# MINI51XAE_v1 register map
File version: 1.0
Registers are 32-bit, read-write, reset 0x0 unless marked. A register's access mark holds for its fields unless they carry their own. Offsets are from the block's base; [hi:lo] are bit positions.

## SYS — SYS Register Map
Base 0x50000000
0x00 SYS_PDID ro reset not defined — Part Device Identification Number Register
  [31:0] PDID — Product Device Identification Number. This register reflects the device part number code. Software can read this register to identify which device is used.
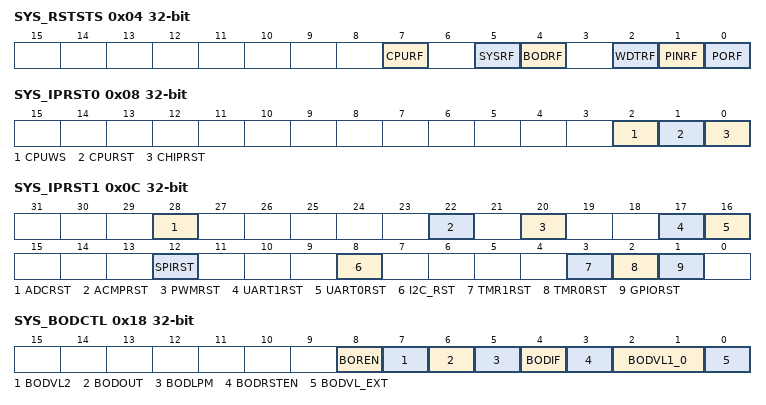
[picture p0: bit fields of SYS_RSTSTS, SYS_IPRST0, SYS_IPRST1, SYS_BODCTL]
0x04 SYS_RSTSTS (reset mask 0xFFFFFF00) — System Reset Source Register
  [7] CPURF — CPU Reset Flag. The CPURF flag is set by hardware if software writes CPURST (SYS_IPRST0[1]) 1 to reset Cortex-M0 core and Flash memory controller (FMC). Note: Software can write 1 to clear this bit to zero.
    0=No reset from CPU; 1=Cortex-M0 core and FMC are reset by software setting CPURST to 1
  [5] SYSRF — MCU Reset Flag. The SYSRF flag is set by the "reset signal" from the Cortex-M0 core to indicate the previous reset source. Note: Software can write 1 to clear this bit to zero.
    0=No reset from Cortex-M0; 1=The Cortex-M0 had issued the reset signal to reset the system by writing 1 to bit SYSRESETREQ (AIRCR[2]), Application Interrupt and Reset Control Register, address = 0xE000ED0C) in system control registers of Cortex-M0 core
  [4] BODRF — Brown-Out Detector Reset Flag. The BODRF flag is set by the "reset signal" from the Brown-out Detector to indicate the previous reset source. Note: Software can write 1 to clear this bit to zero.
    0=No reset from BOD; 1=The BOD had issued the reset signal to reset the system
  [2] WDTRF — Watchdog Reset Flag. The RSTS_WDT flag is set by the "reset signal" from the Watchdog timer to indicate the previous reset source. Note: Software can write 1 to clear this bit to zero.
    0=No reset from Watchdog timer; 1=The Watchdog timer had issued the reset signal to reset the system
  [1] PINRF — Reset Pin Reset Flag. The PINRF flag is set by the "reset signal" from the /RESET pin to indicate the previous reset source. Note: Software can write 1 to clear this bit to zero.
    0=No reset from pin /RESET pin; 1=The /RESET pin had issued the reset signal to reset the system
  [0] PORF — Power-On Reset Flag. The PORF flag is set by the "reset signal", which is from the Power-On Reset (POR) controller or bit CHIPRST (SYS_IPRST0[0]), to indicate the previous reset source. Note: Software can write 1 to clear this bit to zero.
    0=No reset from POR or CHIPRST; 1=The Power-on-Reset (POR) or CHIPRST had issued the reset signal to reset the system
0x08 SYS_IPRST0 — Peripheral Reset Control Resister 1
  [2] CPUWS — CPU Wait-State Control For Flash Memory Access. 0: Insert one wait-state when access Flash. 1: Non-insert wait-state when access Flash. Note: When HCLK frequency is faster than 44MHz, insert one wait state is necessary.
  [1] CPURST — CPU Kernel One Shot Reset. Setting this bit will reset the CPU kernel, and this bit will automatically return to 0 after the 2 clock cycles. Note: This bit is the protected bit, and programming it needs to write 0x59, 0x16, and 0x88 to address 0x5000_0100 to disable register protection. Refer to the register REGLCTL at address SYS_BA + 0x100.
    0=Normal; 1=Reset CPU
  [0] CHIPRST — CHIP One-Shot Reset (Write Protect). Setting this bit will reset the CHIP, including CPU kernel and all peripherals, and this bit will automatically return to 0 after the 2 clock cycles. The CHIPRST is the same as the POR reset, and all the chip module is reset and the chip settings from flash are also reload. Note: This bit is the protected bit, and programming it needs to write 0x59, 0x16, and 0x88 to address 0x5000_0100 to disable register protection. Refer to the register REGLCTL at address SYS_BA + 0x100.
    0=Chip normal operation; 1=CHIP one-shot reset
0x0C SYS_IPRST1 — Peripheral Reset Control Resister 2
  [28] ADCRST — ADC Controller Reset
    0=ADC block normal operation; 1=ADC block reset
  [22] ACMPRST — ACMP Controller Reset
    0=ACMP block normal operation; 1=ACMP block reset
  [20] PWMRST — PWM Controller Reset
    0=PWM block normal operation; 1=PWM block reset
  [17] UART1RST — UART1 Controller Reset
    0=UART1 normal operation; 1=UART1 block reset
  [16] UART0RST — UART0 Controller Reset
    0=UART0 normal operation; 1=UART0 block reset
  [12] SPIRST — SPI Controller Reset
    0=SPI block normal operation; 1=SPI block reset
  [8] I2C_RST — I2C Controller Reset
    0=I2C normal operation; 1=I2C block reset
  [3] TMR1RST — Timer1 Controller Reset
    0=Timer1 normal operation; 1=Timer1 block reset
  [2] TMR0RST — Timer0 Controller Reset
    0=Timer0 normal operation; 1=Timer0 block reset
  [1] GPIORST — GPIO (P0~P5) Controller Reset
    0=GPIO normal operation; 1=GPIO reset
0x18 SYS_BODCTL (reset mask 0xFFFFFF00) — Brown-out Detector Control Register
  [8] BOREN — Brown-Out Reset Enable. The bit will enable BOR reset function. When VDD5V lower than 1.7v BOR will reset whole chip. 0: Disable. 1: Enable
  [7] BODVL2 — Brown-Out Detector Threshold Voltage Selection (Initiated Write-Protected Bit). The default value is set by flash controller user configuration register config0 bit[19].
  [6] BODOUT — Brown-Out Detector Output State
    0=Brown-out Detector status output is 0, the detected voltage is higher than BODVL setting; 1=Brown-out Detector status output is 1, the detected voltage is lower than BODVL setting
  [5] BODLPM — Brown-Out Detector Low Power Mode (Write-Protected). The BOD consumes about 100uA in normal mode, the low power mode can reduce the current to about 1/10 but slow the BOD response.
    0=BOD operate in normal mode (default); 1=Enable the BOD low power mode
  [4] BODIF — Brown-Out Detector Interrupt Flag
    0=Brown-out Detector does not detect any voltage draft at VDD down through or up through the voltage of BODVL setting; 1=When Brown-out Detector detects the VDD is dropped through the voltage of BODVL setting or the VDD is raised up through the voltage of BODVL setting, this bit is set to 1 and the Brown-out interrupt is requested if Brown-out interrupt is enabled
  [3] BODRSTEN — Brown-Out Reset Enable (Initiated And Write-Protected Bit). The default value is set by flash controller user configuration register config0 bit[20]. When the BOREN is enabled and the interrupt is asserted, the interrupt will be kept till the BOREN is set to 0. The interrupt for CPU can be blocked by disabling the NVIC in CPU for BOD interrupt or disable the interrupt source by disabling the BOREN and then re-enabling the BOREN function if the BOD function is required.
    0=Brown-out "INTERRUPT" function Enabled; when the Brown-out Detector function is enable and the detected voltage is lower than the threshold, then assert a signal to interrupt the Cortex-M0 CPU; 1=Brown-out "RESET" function Enabled; when the Brown-out Detector function is enable and the detected voltage is lower than the threshold then assert a signal to reset the chip
  [2:1] BODVL1_0 — Brown-Out Detector Threshold Voltage Selection (Initiated Write-Protected Bit)
  [0] BODVL_EXT — Brown-Out Detector Selection Extension (Initiated Write-Protected Bit)
    0=Brown-out detector threshold voltage is selected by the table defined in BODVL[1:0]; 1=Brown-out detector threshold voltage is selected by BODVL[2:0] defined as below
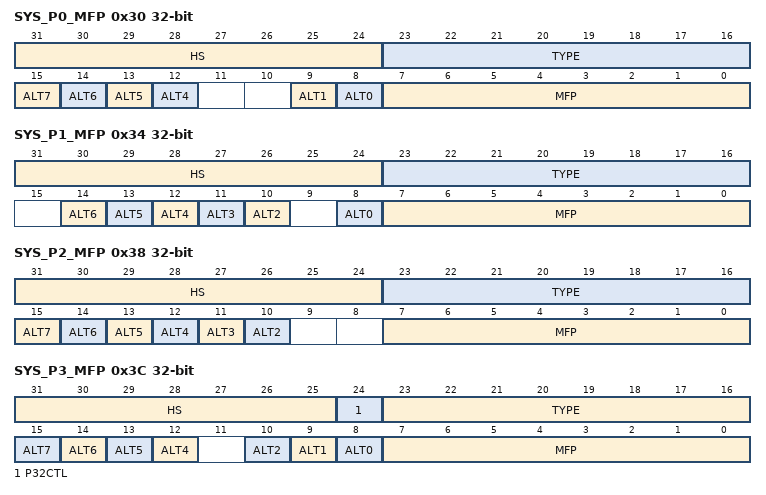
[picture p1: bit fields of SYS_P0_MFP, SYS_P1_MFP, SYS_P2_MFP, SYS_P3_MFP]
0x30 SYS_P0_MFP — P0 Multiple Function and Input Type Control Register
  [31:24] HS — P0[7:0] Slew Rate Control
    0=P0[7:0] Low slew rate output, 16MHz available; 1=P0[7:0] High slew rate output, 24MHz available
  [23:16] TYPE — P0[7:0] Input Schmitt Trigger Function Enable
    0=P0[7:0] I/O input Schmitt Trigger function Disabled; 1=P0[7:0] I/O input Schmitt Trigger function Enabled
  [15] ALT7 — P0.7 Alternate Function Selection
  [14] ALT6 — P0.6 Alternate Function Selection
  [13] ALT5 — P0.5 Alternate Function Selection
  [12] ALT4 — P0.4 Alternate Function Selection
  [9] ALT1 — P0.1 Alternate Function Selection
  [8] ALT0 — P0.0 Alternate Function Selection
  [7:0] MFP — P0 Multiple Function Selection. The pin function of P0 depends on P0_MFP and ALT. Refer to ALT Description for details.
0x34 SYS_P1_MFP — P1 Multiple Function and Input Type Control Register
  [31:24] HS — P1[7:0] Slew Rate Control
    0=P1[7:0] Low slew rate output, 16MHz available; 1=P1[7:0] High slew rate output, 24MHz available
  [23:16] TYPE — P1[7:0] Input Schmitt Trigger Function Enable
    0=P1[7:0] I/O input Schmitt Trigger function Disabled; 1=P1[7:0] I/O input Schmitt Trigger function Enabled
  [14] ALT6 — P1.6 Alternate Function Selection
  [13] ALT5 — P1.5 Alternate Function Selection
  [12] ALT4 — P1.4 Alternate Function Selection
  [11] ALT3 — P1.3 Alternate Function Selection
  [10] ALT2 — P1.2 Alternate Function Selection
  [8] ALT0 — P1.0 Alternate Function Selection
  [7:0] MFP — P1 Multiple Function Selection. The pin function of P1 depends on MFP and ALT. Refer to P1_ALT Description for details.
0x38 SYS_P2_MFP — P2 Multiple Function and Input Type Control Register
  [31:24] HS — P2[7:0] Slew Rate Control
    0=P2[7:0] Low slew rate output, 16MHz available; 1=P2[7:0] High slew rate output, 24MHz available
  [23:16] TYPE — P2[7:0] Input Schmitt Trigger Function Enable
    0=P2[7:0] I/O input Schmitt Trigger function Disabled; 1=P2[7:0] I/O input Schmitt Trigger function Enabled
  [15] ALT7 — P2.7 Alternate Function Selection
  [14] ALT6 — P2.6 Alternate Function Selection
  [13] ALT5 — P2.5 Alternate Function Selection
  [12] ALT4 — P2.4 Alternate Function Selection
  [11] ALT3 — P2.3 Alternate Function Selection
  [10] ALT2 — P2.2 Alternate Function Selection
  [7:0] MFP — P2 Multiple Function Selection. The pin function of P2 depends on P2_MFP and ALT. Refer to ALT Description for details.
0x3C SYS_P3_MFP — P3 Multiple Function and Input Type Control Register
  [31:25] HS — P3[6:0] Slew Rate Control
    0=P3[6:0] Low slew rate output, 16MHz available; 1=P3[6:0] High slew rate output, 24MHz available
  [24] P32CTL — P3.2 Alternate Function Selection Extension
    0=P3.2 is set by ALT[2] and MFP[2]; 1=P3.2 is set to CPP1 of ACMP1
  [23:16] TYPE — P3[7:0] Input Schmitt Trigger Function Enable
    0=P3[7:0] I/O input Schmitt Trigger function Disabled; 1=P3[7:0] I/O input Schmitt Trigger function Enabled
  [15] ALT7 — P3.7 Alternate Function Selection
  [14] ALT6 — P3.6 Alternate Function Selection
  [13] ALT5 — P3.5 Alternate Function Selection
  [12] ALT4 — P3.4 Alternate Function Selection
  [10] ALT2 — P3.2 Alternate Function Selection
  [9] ALT1 — P3.1 Alternate Function Selection
  [8] ALT0 — P3.0 Alternate Function Selection
  [7:0] MFP — P3 Multiple Function Selection. The pin function of P3 depends on MFP and ALT. Refer to ALT Description for details.
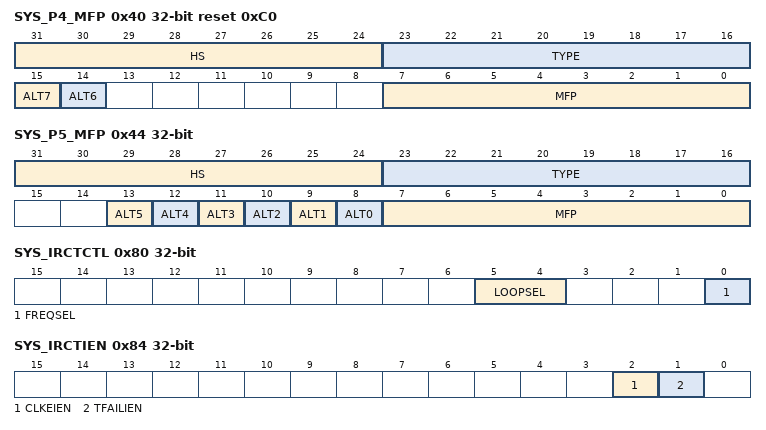
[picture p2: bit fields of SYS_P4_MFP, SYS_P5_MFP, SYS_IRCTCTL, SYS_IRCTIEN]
0x40 SYS_P4_MFP reset 0xC0 — P4 Multiple Function and Input Type Control Register
  [31:24] HS — P4[7:0] Slew Rate Control
    0=P4[7:0] Low slew rate output, 16MHz available; 1=P4[7:0] High slew rate output, 24MHz available
  [23:16] TYPE — P4[7:0] Input Schmitt Trigger Function Enable
    0=P4[7:0] I/O input Schmitt Trigger function Disabled; 1=P4[7:0] I/O input Schmitt Trigger function Enabled
  [15] ALT7 — P4.7 Alternate Function Selection
  [14] ALT6 — P4.6 Alternate Function Selection
  [7:0] MFP — P4 Multiple Function Selection. The pin function of P4 depends on MFP and P4_ALT. Refer to ALT Description for details.
0x44 SYS_P5_MFP — P5 Multiple Function and Input Type Control Register
  [31:24] HS — P5[7:0] Slew Rate Control
    0=P5[7:0] Low slew rate output, 16MHz available; 1=P5[7:0] High slew rate output, 24MHz available
  [23:16] TYPE — P5[7:0] Input Schmitt Trigger Function Enable
    0=P5[7:0] I/O input Schmitt Trigger function Disabled; 1=P5[7:0] I/O input Schmitt Trigger function Enabled
  [13] ALT5 — P5.5 Alternate Function Selection
  [12] ALT4 — P5.4 Alternate Function Selection
  [11] ALT3 — P5.3 Alternate Function Selection
  [10] ALT2 — P5.2 Alternate Function Selection
  [9] ALT1 — P5.1 Alternate Function Selection
  [8] ALT0 — P5.0 Alternate Function Selection
  [7:0] MFP — P5 Multiple Function Selection. The pin function of P5 depends on MFP and ALT. Refer to ALT Description for details.
0x48 SYS_EINT0SEL — PIN selection
  [0] SEL — INT0 SEL GPB3
    0=INT0 source is P3.2; 1=INT0 source is P1.3
0x80 SYS_IRCTCTL — HFIRC Trim Control Register
  [5:4] LOOPSEL — Trim Calculation Loop. This field defines trim value calculation based on the number of LXT clock. For example, if LOOPSEL is set as "00", auto trim circuit will calculate trim value based on the average frequency difference in 4 LXT clock. This field also defines how many times the auto trim circuit will try to update the HFIRC trim value before the frequency of HFIRC is locked. Once the HFIRC is locked, the internal trim value update counter will be reset. If the trim value update counter reaches this limitation value and frequency of HFIRC is still not locked, the auto trim operation will be disabled and FREQSEL will be cleared to 0.
    0=Trim value calculation is based on average difference in 4 LXT clock and trim retry count limitation is 64; 1=Trim value calculation is based on average difference in 8 LXT clock and trim retry count limitation is 128; 2=Trim value calculation is based on average difference in 16 LXT clock and trim retry count limitation is 256; 3=Trim value calculation is based on average difference in 32 LXT clock and trim retry count limitation is 512
  [0] FREQSEL — Trim Frequency Selection. This bit is to enable the HFIRC auto trim. When setting this bit to 1, the HFIRC auto trim function will trim HFIRC to 22.1184 MHz automatically based on the LXT reference clock. During auto trim operation, if LXT clock error is detected or trim retry limitation count reached, this field will be cleared to 0 automatically.
    0=HFIRC auto trim function Disabled; 1=HFIRC auto trim function Enabled and HFIRC trimmed to 22.1184 MHz
0x84 SYS_IRCTIEN — HFIRC Trim Interrupt Enable Register
  [2] CLKEIEN — LXT Clock Error Interrupt Enable. This bit controls if CPU could get an interrupt while LXT clock is inaccurate during auto trim operation. If this bit is high, and CLKERRIF is set during auto trim operation, an interrupt will be triggered to notify the LXT clock frequency is inaccurate.
    0=CLKERRIF status Disabled to trigger an interrupt to CPU; 1=CLKERRIF status Enabled to trigger an interrupt to CPU
  [1] TFAILIEN — Trim Failure Interrupt Enable. This bit controls if an interrupt will be triggered while HFIRC trim value update limitation count is reached and HFIRC frequency is still not locked on target frequency set by FREQSEL. If this bit is high and TFAILIF is set during auto trim operation, an interrupt will be triggered to notify that HFIRC trim value update limitation count is reached.
    0=TFAILIF status Disabled to trigger an interrupt to CPU; 1=TFAILIF status Enabled to trigger an interrupt to CPU
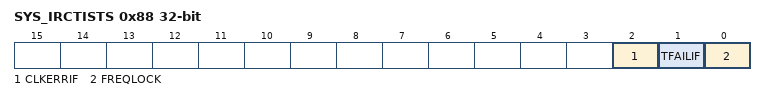
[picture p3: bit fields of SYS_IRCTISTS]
0x88 SYS_IRCTISTS — HFIRC Trim Interrupt Status Register
  [2] CLKERRIF — LXT Clock Error Interrupt Status. This bit indicates that LXT clock frequency is inaccuracy. Once this bit is set, the auto trim operation stopped and FREQSEL will be cleared to 0 by hardware automatically. If this bit is set and CLKEIEN is high, an interrupt will be triggered to notify the LXT clock frequency is inaccuracy. Software can write 1 to clear this bit to zero.
    0=LXT clock frequency is accuracy; 1=LXT clock frequency is inaccuracy
  [1] TFAILIF — Trim Failure Interrupt Status. This bit indicates that HFIRC trim value update limitation count reached and HFIRC clock frequency still doesn't lock. Once this bit is set, the auto trim operation stopped and FREQSEL will be cleared to 0 by hardware automatically. If this bit is set and TFAILIEN is high, an interrupt will be triggered to notify that HFIRC trim value update limitation count was reached. Software can write 1 to clear this bit to zero.
    0=Trim value update limitation count is not reached; 1=Trim value update limitation count is reached and HFIRC frequency is still not locked
  [0] FREQLOCK — HFIRC Frequency Lock Status. This bit indicates the HFIRC frequency locked in 22.1184 MHz. This is a read only status bit and doesn't trigger any interrupt.
0x100 SYS_REGLCTL — Register Write-Protection Control Register
  [0] REGWRPROT ro — Register Write-Protection Disable Index (Read Only)
    0=Write-protection Enabled for writing protected registers. Any write to the protected register is ignored; 1=Write-protection Disabled for writing protected registers
  [7:0] REGPROTDIS wo — Register Write-Protection Code (Write Only). Some registers have write-protection function. Writing these registers have to disable the protected function by writing the sequence value 0x59, 0x16, 0x88 to this field. After this sequence is completed, the REGWRPROT bit will be set to 1 and write-protection registers can be normal write.
